# PIC32MM0016GPL020 register map
Vendor: Microchip
Registers are 32-bit, read-write, reset 0x0 unless marked. A register's access mark holds for its fields unless they carry their own. Addresses are absolute, and some are shared; only a register's first bit layout is shown; [hi:lo] are bit positions; {n}, {i} and the like mark numbered series.

## CCP2
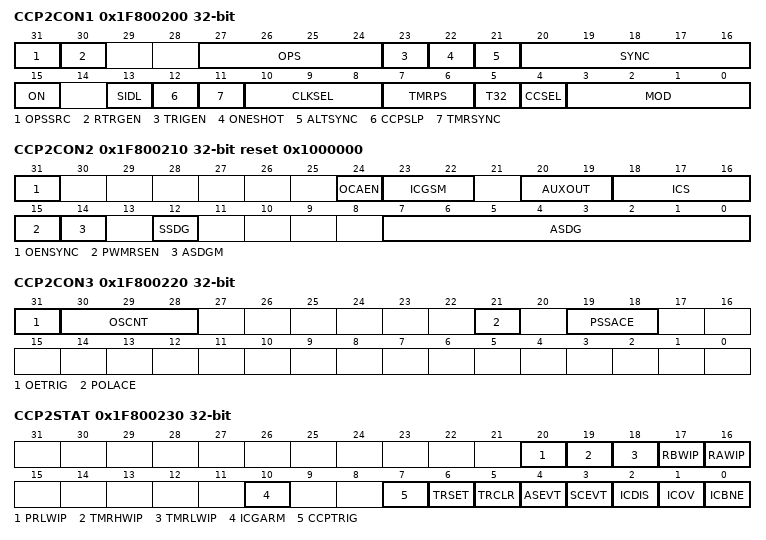
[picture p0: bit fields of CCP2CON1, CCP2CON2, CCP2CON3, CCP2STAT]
0x1F800200 CCP2CON1
  [31] OPSSRC, [30] RTRGEN, [27:24] OPS, [23] TRIGEN, [22] ONESHOT, [21] ALTSYNC, [20:16] SYNC, [15] ON, [13] SIDL, [12] CCPSLP, [11] TMRSYNC, [10:8] CLKSEL, [7:6] TMRPS, [5] T32, [4] CCSEL, [3:0] MOD
0x1F800210 CCP2CON2 reset 0x1000000
  [31] OENSYNC, [24] OCAEN, [23:22] ICGSM, [20:19] AUXOUT, [18:16] ICS, [15] PWMRSEN, [14] ASDGM, [12] SSDG, [7:0] ASDG
0x1F800220 CCP2CON3
  [31] OETRIG, [30:28] OSCNT, [21] POLACE, [19:18] PSSACE
0x1F800230 CCP2STAT
  [20] PRLWIP
  [19] TMRHWIP
  [18] TMRLWIP
  [17] RBWIP
  [16] RAWIP
  [10] ICGARM
  [7] CCPTRIG ro
  [6] TRSET
  [5] TRCLR
  [4] ASEVT — (can only be cleared)
  [3] SCEVT — (can only be cleared)
  [2] ICDIS ro
  [1] ICOV — (can only be cleared)
  [0] ICBNE ro
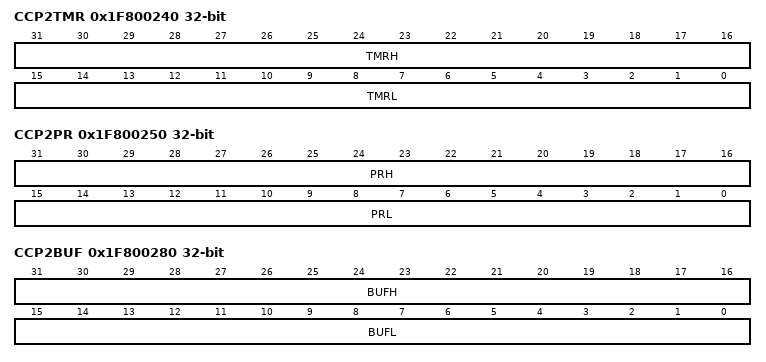
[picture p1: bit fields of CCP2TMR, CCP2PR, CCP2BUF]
0x1F800240 CCP2TMR
  [31:16] TMRH, [15:0] TMRL
0x1F800250 CCP2PR
  [31:16] PRH, [15:0] PRL
0x1F800260 CCP2RA
  [15:0] CMPA
0x1F800270 CCP2RB
  [15:0] CMPB
0x1F800280 CCP2BUF
  [31:16] BUFH, [15:0] BUFL

## CCP3
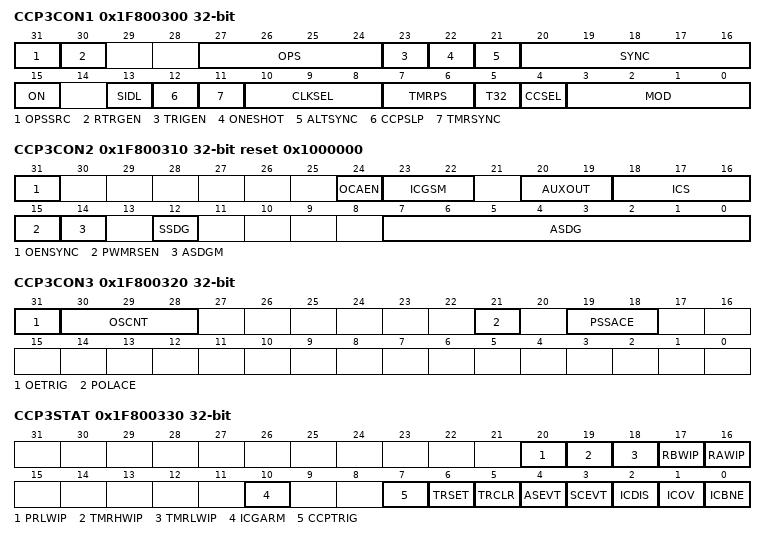
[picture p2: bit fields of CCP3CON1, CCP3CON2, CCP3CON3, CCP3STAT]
0x1F800300 CCP3CON1
  [31] OPSSRC, [30] RTRGEN, [27:24] OPS, [23] TRIGEN, [22] ONESHOT, [21] ALTSYNC, [20:16] SYNC, [15] ON, [13] SIDL, [12] CCPSLP, [11] TMRSYNC, [10:8] CLKSEL, [7:6] TMRPS, [5] T32, [4] CCSEL, [3:0] MOD
0x1F800310 CCP3CON2 reset 0x1000000
  [31] OENSYNC, [24] OCAEN, [23:22] ICGSM, [20:19] AUXOUT, [18:16] ICS, [15] PWMRSEN, [14] ASDGM, [12] SSDG, [7:0] ASDG
0x1F800320 CCP3CON3
  [31] OETRIG, [30:28] OSCNT, [21] POLACE, [19:18] PSSACE
0x1F800330 CCP3STAT
  [20] PRLWIP
  [19] TMRHWIP
  [18] TMRLWIP
  [17] RBWIP
  [16] RAWIP
  [10] ICGARM
  [7] CCPTRIG ro
  [6] TRSET
  [5] TRCLR
  [4] ASEVT — (can only be cleared)
  [3] SCEVT — (can only be cleared)
  [2] ICDIS ro
  [1] ICOV — (can only be cleared)
  [0] ICBNE ro
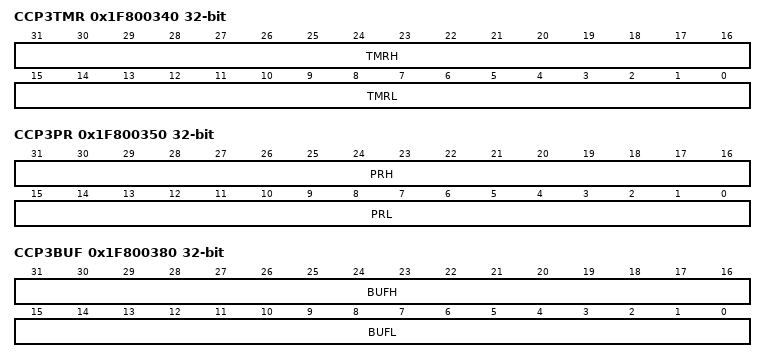
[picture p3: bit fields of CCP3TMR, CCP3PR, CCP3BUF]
0x1F800340 CCP3TMR
  [31:16] TMRH, [15:0] TMRL
0x1F800350 CCP3PR
  [31:16] PRH, [15:0] PRL
0x1F800360 CCP3RA
  [15:0] CMPA
0x1F800370 CCP3RB
  [15:0] CMPB
0x1F800380 CCP3BUF
  [31:16] BUFH, [15:0] BUFL

## UART1
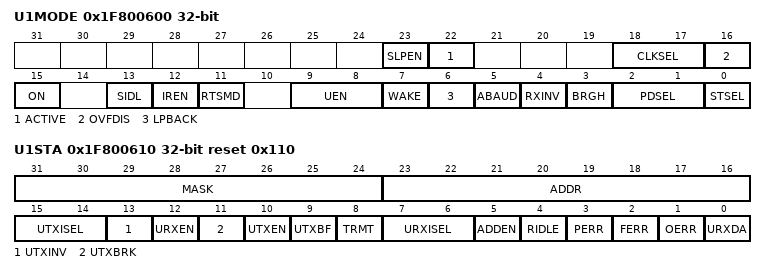
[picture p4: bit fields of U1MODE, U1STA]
0x1F800600 U1MODE
  [23] SLPEN, [22] ACTIVE, [18:17] CLKSEL, [16] OVFDIS, [15] ON, [13] SIDL, [12] IREN, [11] RTSMD, [9:8] UEN, [7] WAKE, [6] LPBACK, [5] ABAUD, [4] RXINV, [3] BRGH, [2:1] PDSEL, [0] STSEL
0x1F800610 U1STA reset 0x110
  [31:24] MASK
  [23:16] ADDR
  [15:14] UTXISEL
  [13] UTXINV
  [12] URXEN
  [11] UTXBRK
  [10] UTXEN
  [9] UTXBF ro
  [8] TRMT ro
  [7:6] URXISEL
  [5] ADDEN
  [4] RIDLE ro
  [3] PERR ro
  [2] FERR ro
  [1] OERR — (can only be cleared)
  [0] URXDA ro
0x1F800620 U1TXREG
  [8:0] U1TXREG
0x1F800630 U1RXREG ro
  [8:0] U1RXREG
0x1F800640 U1BRG
  [19:0] BRG

## UART2
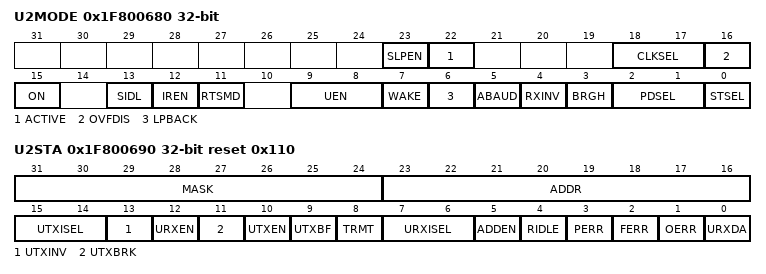
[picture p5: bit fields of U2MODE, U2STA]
0x1F800680 U2MODE
  [23] SLPEN, [22] ACTIVE, [18:17] CLKSEL, [16] OVFDIS, [15] ON, [13] SIDL, [12] IREN, [11] RTSMD, [9:8] UEN, [7] WAKE, [6] LPBACK, [5] ABAUD, [4] RXINV, [3] BRGH, [2:1] PDSEL, [0] STSEL
0x1F800690 U2STA reset 0x110
  [31:24] MASK
  [23:16] ADDR
  [15:14] UTXISEL
  [13] UTXINV
  [12] URXEN
  [11] UTXBRK
  [10] UTXEN
  [9] UTXBF ro
  [8] TRMT ro
  [7:6] URXISEL
  [5] ADDEN
  [4] RIDLE ro
  [3] PERR ro
  [2] FERR ro
  [1] OERR — (can only be cleared)
  [0] URXDA ro
0x1F8006A0 U2TXREG
  [8:0] U2TXREG
0x1F8006B0 U2RXREG ro
  [8:0] U2RXREG
0x1F8006C0 U2BRG
  [19:0] BRG

## ADC
{0x1F800700+0x10*i} ADC1BUF{i} (i=0..15)
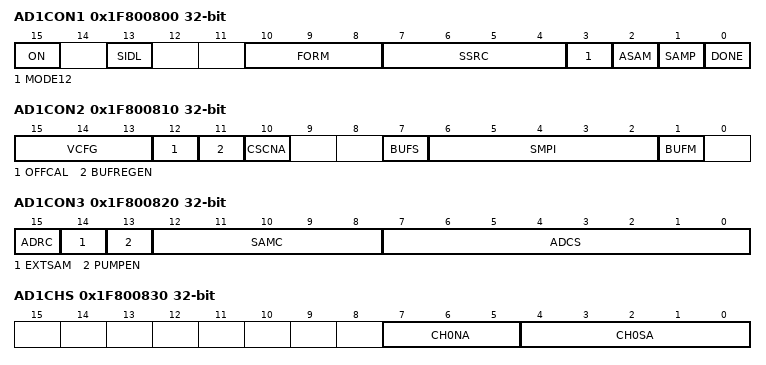
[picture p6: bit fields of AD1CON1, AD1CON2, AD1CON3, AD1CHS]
0x1F800800 AD1CON1
  [15] ON
  [13] SIDL
  [10:8] FORM
  [7:4] SSRC
  [3] MODE12
  [2] ASAM
  [1] SAMP
  [0] DONE — (can only be cleared)
0x1F800810 AD1CON2
  [15:13] VCFG, [12] OFFCAL, [11] BUFREGEN, [10] CSCNA, [7] BUFS ro, [6:2] SMPI, [1] BUFM
0x1F800820 AD1CON3
  [15] ADRC, [14] EXTSAM, [13] PUMPEN, [12:8] SAMC, [7:0] ADCS
0x1F800830 AD1CHS
  [7:5] CH0NA, [4:0] CH0SA
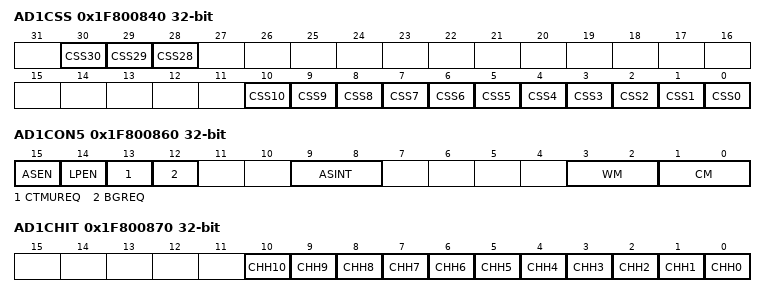
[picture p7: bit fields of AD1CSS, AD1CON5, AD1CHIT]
0x1F800840 AD1CSS reset not defined — (power-on value -xxx-----------------xxxxxxxxxxx)
  [30] CSS30, [29] CSS29, [28] CSS28, [n] CSS{n} (n=0..10)
0x1F800860 AD1CON5
  [15] ASEN, [14] LPEN, [13] CTMUREQ, [12] BGREQ, [9:8] ASINT, [3:2] WM, [1:0] CM
0x1F800870 AD1CHIT
  [n] CHH{n} (n=0..10)
